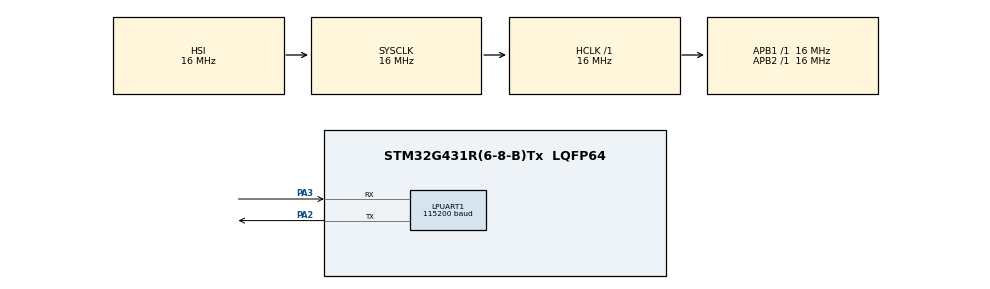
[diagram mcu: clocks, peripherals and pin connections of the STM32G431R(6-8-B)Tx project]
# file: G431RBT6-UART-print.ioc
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Dma.LPUART1_TX.0.Direction=DMA_MEMORY_TO_PERIPH
Dma.LPUART1_TX.0.EventEnable=DISABLE
Dma.LPUART1_TX.0.Instance=DMA1_Channel1
Dma.LPUART1_TX.0.MemDataAlignment=DMA_MDATAALIGN_BYTE
Dma.LPUART1_TX.0.MemInc=DMA_MINC_ENABLE
Dma.LPUART1_TX.0.Mode=DMA_NORMAL
Dma.LPUART1_TX.0.PeriphDataAlignment=DMA_PDATAALIGN_BYTE
Dma.LPUART1_TX.0.PeriphInc=DMA_PINC_DISABLE
Dma.LPUART1_TX.0.Polarity=HAL_DMAMUX_REQ_GEN_RISING
Dma.LPUART1_TX.0.Priority=DMA_PRIORITY_LOW
Dma.LPUART1_TX.0.RequestNumber=1
Dma.LPUART1_TX.0.SignalID=NONE
Dma.LPUART1_TX.0.SyncEnable=DISABLE
Dma.LPUART1_TX.0.SyncPolarity=HAL_DMAMUX_SYNC_NO_EVENT
Dma.LPUART1_TX.0.SyncRequestNumber=1
Dma.LPUART1_TX.0.SyncSignalID=NONE
Dma.Request0=LPUART1_TX
FREERTOS.Tasks01=defaultTask,24,128,StartDefaultTask,Default,NULL,Dynamic,NULL,NULL
FREERTOS.configUSE_NEWLIB_REENTRANT=1
LPUART1.BaudRate=115200
Mcu.Family=STM32G4
Mcu.Name=STM32G431R(6-8-B)Tx
Mcu.Package=LQFP64
NVIC.DMA1_Channel1_IRQn=true\:5\:0\:false\:false\:true\:true\:false\:true\:true
NVIC.PriorityGroup=NVIC_PRIORITYGROUP_4
NVIC.TIM6_DAC_IRQn=true\:15\:0\:false\:false\:true\:false\:false\:true\:true
NVIC.TimeBase=TIM6_DAC_IRQn
NVIC.TimeBaseIP=TIM6
PA2.Mode=Asynchronous
PA2.Signal=LPUART1_TX
PA3.Mode=Asynchronous
PA3.Signal=LPUART1_RX
ProjectManager.HeapSize=0x200
ProjectManager.StackSize=0x400
ProjectManager.TargetToolchain=STM32CubeIDE
RCC.AHBFreq_Value=16000000
RCC.APB1Freq_Value=16000000
RCC.APB1TimFreq_Value=16000000
RCC.APB2Freq_Value=16000000
RCC.APB2TimFreq_Value=16000000
RCC.CortexFreq_Value=16000000
RCC.EXTERNAL_CLOCK_VALUE=12288000
RCC.HCLKFreq_Value=16000000
RCC.HSE_VALUE=8000000
RCC.HSI48_VALUE=48000000
RCC.HSI_VALUE=16000000
RCC.LSE_VALUE=32768
RCC.SYSCLKFreq_VALUE=16000000
RCC.USBFreq_Value=64000000
RCC.VCOOutputFreq_Value=128000000
VP_FREERTOS_VS_CMSIS_V2.Mode=CMSIS_V2
VP_SYS_VS_tim6.Mode=TIM6
board=custom

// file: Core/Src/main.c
/* USER CODE BEGIN Header */
/**
  ******************************************************************************
  * @file           : main.c
  * @brief          : Main program body
  ******************************************************************************
  * @attention
  *
  * Copyright (c) 2023 STMicroelectronics.
  * All rights reserved.
  *
  * This software is licensed under terms that can be found in the LICENSE file
  * in the root directory of this software component.
  * If no LICENSE file comes with this software, it is provided AS-IS.
  *
  ******************************************************************************
  */
/* USER CODE END Header */
#include "main.h"
#include "cmsis_os.h"

/* USER CODE BEGIN Includes */
#include <stdio.h>
#include <stdarg.h>
/* USER CODE END Includes */

UART_HandleTypeDef hlpuart1;
DMA_HandleTypeDef hdma_lpuart1_tx;

/* Definitions for defaultTask */
osThreadId_t defaultTaskHandle;
const osThreadAttr_t defaultTask_attributes = {
  .name = "defaultTask",
  .priority = (osPriority_t) osPriorityNormal,
  .stack_size = 128 * 4
};

void SystemClock_Config(void);
static void MX_GPIO_Init(void);
static void MX_DMA_Init(void);
static void MX_LPUART1_UART_Init(void);
void StartDefaultTask(void *argument);

/* USER CODE BEGIN PFP */
#ifdef __GNUC__
/* With GCC, small printf (option LD Linker->Libraries->Small printf
   set to 'Yes') calls __io_putchar() */
#define PUTCHAR_PROTOTYPE int __io_putchar(int ch)
#else
#define PUTCHAR_PROTOTYPE int fputc(int ch, FILE *f)
#endif /* __GNUC__ */
/* USER CODE END PFP */

int main(void)
{

  /* MCU Configuration--------------------------------------------------------*/

  /* Reset of all peripherals, Initializes the Flash interface and the Systick. */
  HAL_Init();

  /* Configure the system clock */
  SystemClock_Config();

  /* Initialize all configured peripherals */
  MX_GPIO_Init();
  MX_DMA_Init();
  MX_LPUART1_UART_Init();

  /* Init scheduler */
  osKernelInitialize();

  /* Create the thread(s) */
  /* creation of defaultTask */
  defaultTaskHandle = osThreadNew(StartDefaultTask, NULL, &defaultTask_attributes);

  /* Start scheduler */
  osKernelStart();

  /* We should never get here as control is now taken by the scheduler */
  /* Infinite loop */
  while (1)
  {

  }
}

void SystemClock_Config(void)
{
  RCC_OscInitTypeDef RCC_OscInitStruct = {0};
  RCC_ClkInitTypeDef RCC_ClkInitStruct = {0};

  /** Configure the main internal regulator output voltage
  */
  HAL_PWREx_ControlVoltageScaling(PWR_REGULATOR_VOLTAGE_SCALE1);

  /** Initializes the RCC Oscillators according to the specified parameters
  * in the RCC_OscInitTypeDef structure.
  */
  RCC_OscInitStruct.OscillatorType = RCC_OSCILLATORTYPE_HSI;
  RCC_OscInitStruct.HSIState = RCC_HSI_ON;
  RCC_OscInitStruct.HSICalibrationValue = RCC_HSICALIBRATION_DEFAULT;
  RCC_OscInitStruct.PLL.PLLState = RCC_PLL_NONE;
  if (HAL_RCC_OscConfig(&RCC_OscInitStruct) != HAL_OK)
  {
    Error_Handler();
  }

  /** Initializes the CPU, AHB and APB buses clocks
  */
  RCC_ClkInitStruct.ClockType = RCC_CLOCKTYPE_HCLK|RCC_CLOCKTYPE_SYSCLK
                              |RCC_CLOCKTYPE_PCLK1|RCC_CLOCKTYPE_PCLK2;
  RCC_ClkInitStruct.SYSCLKSource = RCC_SYSCLKSOURCE_HSI;
  RCC_ClkInitStruct.AHBCLKDivider = RCC_SYSCLK_DIV1;
  RCC_ClkInitStruct.APB1CLKDivider = RCC_HCLK_DIV1;
  RCC_ClkInitStruct.APB2CLKDivider = RCC_HCLK_DIV1;

  if (HAL_RCC_ClockConfig(&RCC_ClkInitStruct, FLASH_LATENCY_0) != HAL_OK)
  {
    Error_Handler();
  }
}

static void MX_LPUART1_UART_Init(void)
{

  hlpuart1.Instance = LPUART1;
  hlpuart1.Init.BaudRate = 115200;
  hlpuart1.Init.WordLength = UART_WORDLENGTH_8B;
  hlpuart1.Init.StopBits = UART_STOPBITS_1;
  hlpuart1.Init.Parity = UART_PARITY_NONE;
  hlpuart1.Init.Mode = UART_MODE_TX_RX;
  hlpuart1.Init.HwFlowCtl = UART_HWCONTROL_NONE;
  hlpuart1.Init.OneBitSampling = UART_ONE_BIT_SAMPLE_DISABLE;
  hlpuart1.Init.ClockPrescaler = UART_PRESCALER_DIV1;
  hlpuart1.AdvancedInit.AdvFeatureInit = UART_ADVFEATURE_NO_INIT;
  if (HAL_UART_Init(&hlpuart1) != HAL_OK)
  {
    Error_Handler();
  }
  if (HAL_UARTEx_SetTxFifoThreshold(&hlpuart1, UART_TXFIFO_THRESHOLD_1_8) != HAL_OK)
  {
    Error_Handler();
  }
  if (HAL_UARTEx_SetRxFifoThreshold(&hlpuart1, UART_RXFIFO_THRESHOLD_1_8) != HAL_OK)
  {
    Error_Handler();
  }
  if (HAL_UARTEx_DisableFifoMode(&hlpuart1) != HAL_OK)
  {
    Error_Handler();
  }

}

static void MX_DMA_Init(void)
{

  /* DMA controller clock enable */
  __HAL_RCC_DMAMUX1_CLK_ENABLE();
  __HAL_RCC_DMA1_CLK_ENABLE();

  /* DMA interrupt init */
  /* DMA1_Channel1_IRQn interrupt configuration */
  HAL_NVIC_SetPriority(DMA1_Channel1_IRQn, 5, 0);
  HAL_NVIC_EnableIRQ(DMA1_Channel1_IRQn);

}

static void MX_GPIO_Init(void)
{

  /* GPIO Ports Clock Enable */
  __HAL_RCC_GPIOA_CLK_ENABLE();

}

/* USER CODE BEGIN 4 */
static void UARTPrintf(const char *pFormat,...)
{
	char buffer[64];
	va_list args;
	va_start(args, pFormat);
	__disable_irq();
	int len = vsprintf(buffer, pFormat, args);
	__enable_irq();

	for (int i = 0; i < len; i++)
	{
		__disable_irq();
		HAL_UART_Transmit(&hlpuart1, (uint8_t*) &buffer[i], 1, HAL_MAX_DELAY);
		__enable_irq();
	}
	va_end(args);
}

/* USER CODE END 4 */

void StartDefaultTask(void *argument)
{
  /* USER CODE BEGIN 5 */
  /* Infinite loop */
  for(;;)
  {
	  UARTPrintf("\n\r Start Default Task\n\r");
	  osDelay(1000);
  }
  /* USER CODE END 5 */
}

void HAL_TIM_PeriodElapsedCallback(TIM_HandleTypeDef *htim)
{
  if (htim->Instance == TIM6) {
    HAL_IncTick();
  }
}

void Error_Handler(void)
{
  __disable_irq();
  while (1)
  {
  }
}
